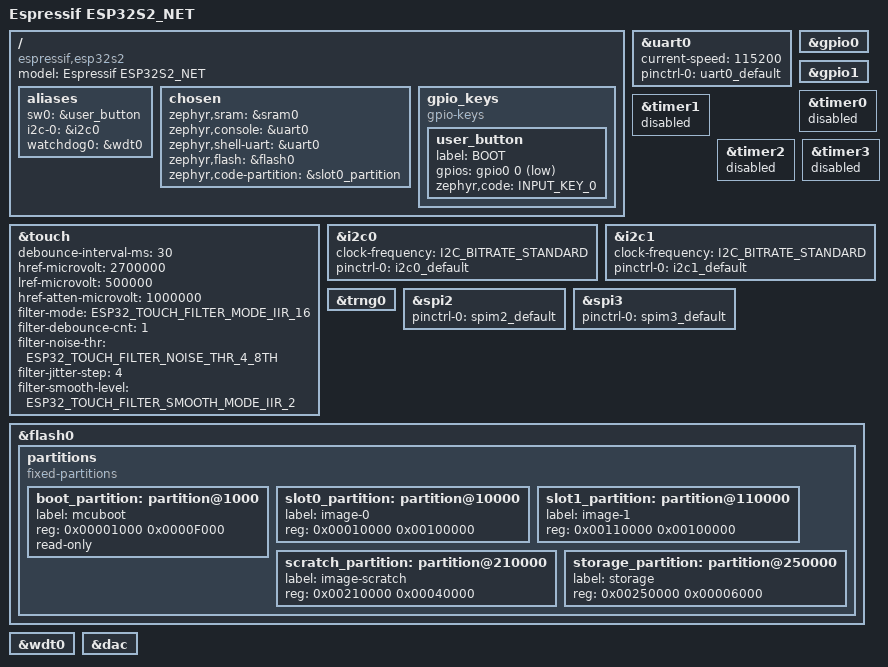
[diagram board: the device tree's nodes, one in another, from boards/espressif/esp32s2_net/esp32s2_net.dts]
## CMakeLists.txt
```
# SPDX-License-Identifier: Apache-2.0

cmake_minimum_required(VERSION 3.20.0)

list(APPEND BOARD_ROOT ${CMAKE_CURRENT_SOURCE_DIR})
find_package(Zephyr REQUIRED HINTS $ENV{ZEPHYR_BASE})

project(esp32s2_net)

target_sources(app PRIVATE 
	src/main.c
	src/fonts/yahei_14.c
	src/lv_wifi.c
	src/wifi_icons.c
	src/mqtt.c
	src/lv_log.c
)
```

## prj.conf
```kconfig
# Remove the banner when start log.
CONFIG_BOOT_BANNER=n

# =============================================================================
# Log configuration
# =============================================================================
CONFIG_LOG=y
CONFIG_LOG_BACKEND_UART=y
# 关闭 shell 日志后端，否则日志由 UART 后端和 shell 后端各打印一遍
# （shell 后端带提示符擦除/重画转义序列，minicom 里表现为整行重复）
CONFIG_SHELL_LOG_BACKEND=n
CONFIG_LOG_PROCESS_THREAD_STACK_SIZE=1024

# =============================================================================
# Shell
# =============================================================================
CONFIG_SHELL=y
CONFIG_SHELL_BACKEND_SERIAL=y
CONFIG_THREAD_MONITOR=y
CONFIG_INIT_STACKS=y
CONFIG_THREAD_STACK_INFO=y
CONFIG_THREAD_NAME=y

# =============================================================================
# Display configuration
# =============================================================================
CONFIG_DISPLAY=y
CONFIG_MIPI_DBI=y
CONFIG_MIPI_DBI_SPI=y
CONFIG_ST7789V=y
CONFIG_LVGL=y
CONFIG_LV_COLOR_DEPTH_16=y
# CONFIG_LV_COLOR_16_SWAP=y  # 若点亮后颜色红蓝反转，再开启
CONFIG_LV_Z_VDB_SIZE=5
CONFIG_LV_Z_BITS_PER_PIXEL=16
CONFIG_LV_Z_MEM_POOL_SIZE=16384
CONFIG_LV_FONT_MONTSERRAT_12=y
CONFIG_LV_FONT_MONTSERRAT_14=y
CONFIG_LV_FONT_MONTSERRAT_16=y
CONFIG_LV_FONT_UNSCII_8=y
CONFIG_MAIN_STACK_SIZE=3072

# =============================================================================
# Wi-Fi configuration（与官方 esp32s2.conf 完全一致，最小验证配置）
# =============================================================================
CONFIG_WIFI=y
CONFIG_WIFI_ESP32=y
CONFIG_WIFI_LOG_LEVEL_INF=y
CONFIG_ESP32_WIFI_STA_AUTO_DHCPV4=y
# 断线自动重连(多扩展器环境下 AP 踢线/信号波动后自动恢复)
CONFIG_ESP32_WIFI_STA_RECONNECT=y
# 临时诊断: 打开 blob 内部调试打印, 抓重连 201 现场
# blob 调试打印: 该 Kconfig 在本版本无消费者, 实际开关是 CONFIG_LOG_DEFAULT_LEVEL
CONFIG_LOG_DEFAULT_LEVEL=3
# iram 优化必须关闭：ESP32-S2 的 IRAM/DRAM 共享同一块 320KB SRAM，
# 开启后 WiFi blob 会多占 ~12.5KB IRAM，与 LVGL 静态缓冲抢内存，
# 导致 dram0_0_seg 链接溢出（实测 overflow ~6.5KB）。
CONFIG_ESP32_WIFI_IRAM_OPT=n
CONFIG_ESP32_WIFI_RX_IRAM_OPT=n

# =============================================================================
# Networking stack（与官方 esp32s2.conf 完全一致）
# =============================================================================
CONFIG_NETWORKING=y
CONFIG_NET_L2_ETHERNET=y
CONFIG_NET_IPV4=y
CONFIG_NET_IPV6=n
CONFIG_NET_DHCPV4=y
CONFIG_NET_LOG=y
CONFIG_NET_SHELL=y
CONFIG_NET_L2_WIFI_SHELL=y
CONFIG_NET_PKT_RX_COUNT=8
CONFIG_NET_PKT_TX_COUNT=8
CONFIG_NET_BUF_RX_COUNT=10
CONFIG_NET_BUF_TX_COUNT=10
CONFIG_NET_MAX_CONTEXTS=12
CONFIG_NET_MAX_CONN=8
CONFIG_NET_TX_STACK_SIZE=2048
CONFIG_NET_RX_STACK_SIZE=2048
# 防止扫描结果事件丢失
CONFIG_NET_MGMT_EVENT_QUEUE_SIZE=16
CONFIG_NET_MGMT_EVENT_QUEUE_TIMEOUT=5000

# =============================================================================
# =============================================================================
# MQTT(屏幕百分比值发布, 参考 samples/net/mqtt_publisher)
# =============================================================================
CONFIG_MQTT_LIB=y
CONFIG_NET_TCP=y
CONFIG_NET_SOCKETS_POSIX_NAMES=y
# POSIX fd 表大小: 默认 4, 0-2 被 stdio 占掉后只剩 1 个 socket 槽,
# MQTT 连接时报 ENFILE(-23), 加大到 16
CONFIG_POSIX_MAX_FDS=16
CONFIG_NET_TCP_WORKQ_STACK_SIZE=1536

# =============================================================================
# Memory / Heap（与官方 esp32s2.conf 一致）
# =============================================================================
CONFIG_HEAP_MEM_POOL_SIZE=61440

# =============================================================================
# Entropy（硬件随机数，Wi-Fi 需要）
# =============================================================================
CONFIG_ENTROPY_ESP32_RNG=y

# =============================================================================
# PSRAM configuration（外部 PSRAM = WROVER N4R2 模组上的 2 MB 芯片）
# =============================================================================
# 硬件事实：ESP32-S2 的 DMA（Wi-Fi MAC、GDMA 均如此）只能访问内部 SRAM
# （SOC_DMA_LOW=0x3FFB0000 ~ SOC_DMA_HIGH=0x40000000），
# PSRAM(0x3F800000) 只有 CPU 能经 cache 访问，任何 DMA 缓冲落入 PSRAM 都会失效。
CONFIG_ESP_SPIRAM=y
CONFIG_SPIRAM_MODE_QUAD=y
CONFIG_SPIRAM_TYPE_ESPPSRAM16=y
CONFIG_SPIRAM_SPEED_40M=y
# 从 PSRAM 中划出 1 MB 作为附加堆（spiram heap）
CONFIG_ESP_SPIRAM_HEAP_SIZE=1048576
# 分配阈值：请求 >= 32768 字节走 PSRAM，其余优先走内部堆。
# 保持 32768 的原因：
#   1) 屏幕 SPI DMA 临时缓冲最大 4092 字节（spi_esp32_spim.c），必须留在内部 RAM；
#   2) 应用想用 PSRAM 时直接 k_malloc(>=32KB) 即可。
CONFIG_ESP_HEAP_MIN_EXTRAM_THRESHOLD=32768

# ❌ 不要启用 CONFIG_SPIRAM_FETCH_INSTRUCTIONS / CONFIG_SPIRAM_RODATA：
#    开启后 esp_psram.c 会调用 mmu_config_psram_text_segment() 等函数，
#    而 Zephyr v3.7.2 的 hal 只在 esp32s3 里实现了这些函数
#    （modules/hal/espressif/zephyr/esp32s3/CMakeLists.txt 才编译
#    mmu_psram_flash.c），esp32s2 会直接链接报错 undefined reference。

# ❌ 不要启用 CONFIG_ESP32_WIFI_NET_ALLOC_SPIRAM：
#    它会把网络栈的 .noinit 静态缓冲池放到 PSRAM；ESP32-S2 上这些缓冲
#    最终被 Wi-Fi MAC 以 DMA 方式访问，PSRAM 不可 DMA，会导致扫描/连接失败。
#    （见 zephyrproject-rtos/zephyr issue #74246、#109602）

# ✅ 依赖一个对 hal_espressif 模块的小 patch（esp32s2/esp_wifi_adapter.c）：
#    1) 去掉 g_wifi_feature_caps 里的 CONFIG_FEATURE_CACHE_TX_BUF_BIT
#       （避免 32×1600B 的 cache-TX 缓冲池耗尽内部堆）；
#    2) *_internal_wrapper 改用 k_aligned_alloc()，保证 Wi-Fi 固件的
#       DMA 缓冲永远落在内部 SRAM。
#    patch 文件保存在工程 patches/ 目录，west update 后需重新应用。
```

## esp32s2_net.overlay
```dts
#include <espressif/esp32s2/esp32s2_wrover_n4r2.dtsi>
#include "boards/espressif/esp32s2_net/esp32s2_net-pinctrl.dtsi"
#include <zephyr/dt-bindings/input/input-event-codes.h>
#include <zephyr/dt-bindings/mipi_dbi/mipi_dbi.h>

/ {
	chosen {
		zephyr,display = &display0;
	};

	display: display {
		status = "okay";
		compatible = "zephyr,mipi-dbi-spi";
		
		spi-dev = <&spi3>;
		dc-gpios = <&gpio0 13 GPIO_ACTIVE_HIGH>;
		reset-gpios = <&gpio0 16 GPIO_ACTIVE_LOW>;
		write-only;	

		#address-cells = <1>;
		#size-cells = <0>;

		display0: display0@0 {
			compatible = "sitronix,st7789v";
			status = "okay";
			reg = <0>;
			mipi-max-frequency = <62500000>;
			mipi-mode = <MIPI_DBI_MODE_SPI_4WIRE>;
			/* Kaluga 液晶是 90 度旋转安装：控制器的 320 栅极线驱动
			 * 玻璃的 320 列（宽），240 源极线驱动 240 行（高）。
			 * 面板的 MADCTL 不可靠，采用软件换轴 + 瓦片转置写入 */
			/* swap-xy; */
		
			height = <240>;
			width = <320>;
			x-offset = <0>;
			y-offset = <0>;
			vcom = <0x2B>;
			gctrl = <0x35>;
			vrhs = <0x0f>;
			vdvs = <0x20>;
			mdac = <0x60>;
			lcm = <0x2C>;
			colmod = <0x55>; /* 16-bit/pixel */
			gamma = <0x01>;
			inversion-off;

			/* 功率与时序控制寄存器字节参数 */
			porch-param  = [0C 0C 00 33 33]; /* Porch setting */
			cmd2en-param = [5a 69 02 01];       /* Command2 Enable Parameter */
			pwctrl1-param = [52 A1];         /* Power control */
			pvgam-param  = [D0 00 02 07 0B 1A 31 54 40 29 12 12 12 17];
			nvgam-param  = [D0 00 02 07 05 15 2D 44 44 1c 18 16 1c 1d];
			ram-param    = [00 F8];          /* RAM control setting */
			rgb-param    = [CD 08 14];       /* RGB Interface Control */	
			
				
		};	
		
	};
	
	backlight: backlight {
		compatible = "gpio-leds";
		bl: bl {
			gpios = <&gpio0 6 GPIO_ACTIVE_HIGH>;
			label = "LCD BackLight";
		};
	};

};

&uart0 {
	status = "okay";
};

&spi3 {
	status = "okay";
	#address-cells = <1>;
	#size-cells = <0>;	
	pinctrl-0 = <&spim3_default>;
	pinctrl-names = "default";
};

&spim3_default {
	group1 {
		pinmux = <SPIM3_MISO_GPIO8>,
			 <SPIM3_MOSI_GPIO9>,
			 <SPIM3_CSEL_GPIO11>;
	};
	group2 {
		pinmux = <SPIM3_SCLK_GPIO15>;
		output-low;
	};
};

&wifi {
	status = "okay";
};

&trng0 {
	status = "okay";
};
```

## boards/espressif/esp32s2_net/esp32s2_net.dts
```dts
/*
 * Copyright (c) 2024 Espressif Systems (Shanghai) Co., Ltd.
 *
 * SPDX-License-Identifier: Apache-2.0
 */

/dts-v1/;

#include <espressif/esp32s2/esp32s2_solo_n4r2.dtsi>
#include "esp32s2_net-pinctrl.dtsi"
#include <zephyr/dt-bindings/input/input-event-codes.h>
#include <zephyr/dt-bindings/input/esp32-touch-sensor-input.h>

/ {
	model = "Espressif ESP32S2_NET";
	compatible = "espressif,esp32s2";

	aliases {
		sw0 = &user_button;
		i2c-0 = &i2c0;
		watchdog0 = &wdt0;
	};

	chosen {
		zephyr,sram = &sram0;
		zephyr,console = &uart0;
		zephyr,shell-uart = &uart0;
		zephyr,flash = &flash0;
		zephyr,code-partition = &slot0_partition;
	};

	gpio_keys {
		compatible = "gpio-keys";
		user_button: user_button {
			label = "BOOT";
			gpios = <&gpio0 0 (GPIO_PULL_UP | GPIO_ACTIVE_LOW)>;
			zephyr,code = <INPUT_KEY_0>;
		};
	};
};

&uart0 {
	status = "okay";
	current-speed = <115200>;
	pinctrl-0 = <&uart0_default>;
	pinctrl-names = "default";
};

&gpio0 {
	status = "okay";
};

&gpio1 {
	status = "okay";
};

&touch {
	debounce-interval-ms = <30>;
	href-microvolt = <2700000>;
	lref-microvolt = <500000>;
	href-atten-microvolt = <1000000>;
	filter-mode = <ESP32_TOUCH_FILTER_MODE_IIR_16>;
	filter-debounce-cnt = <1>;
	filter-noise-thr = <ESP32_TOUCH_FILTER_NOISE_THR_4_8TH>;
	filter-jitter-step = <4>;
	filter-smooth-level = <ESP32_TOUCH_FILTER_SMOOTH_MODE_IIR_2>;
};

&timer0 {
	status = "disabled";
};

&timer1 {
	status = "disabled";
};

&timer2 {
	status = "disabled";
};

&timer3 {
	status = "disabled";
};

&i2c0 {
	status = "okay";
	clock-frequency = <I2C_BITRATE_STANDARD>;
	pinctrl-0 = <&i2c0_default>;
	pinctrl-names = "default";
};

&i2c1 {
	clock-frequency = <I2C_BITRATE_STANDARD>;
	pinctrl-0 = <&i2c1_default>;
	pinctrl-names = "default";
};

&trng0 {
	status = "okay";
};

&spi2 {
	#address-cells = <1>;
	#size-cells = <0>;
	status = "okay";
	pinctrl-0 = <&spim2_default>;
	pinctrl-names = "default";
};

&spi3 {
	#address-cells = <1>;
	#size-cells = <0>;
	status = "okay";
	pinctrl-0 = <&spim3_default>;
	pinctrl-names = "default";
};


&flash0 {
	status = "okay";

	partitions {
		compatible = "fixed-partitions";
		#address-cells = <1>;
		#size-cells = <1>;

		/* Reserve 60kB for the bootloader */
		boot_partition: partition@1000 {
			label = "mcuboot";
			reg = <0x00001000 0x0000F000>;
			read-only;
		};

		/* Reserve 1024kB for the application in slot 0 */
		slot0_partition: partition@10000 {
			label = "image-0";
			reg = <0x00010000 0x00100000>;
		};

		/* Reserve 1024kB for the application in slot 1 */
		slot1_partition: partition@110000 {
			label = "image-1";
			reg = <0x00110000 0x00100000>;
		};

		/* Reserve 256kB for the scratch partition */
		scratch_partition: partition@210000 {
			   label = "image-scratch";
			   reg = <0x00210000 0x00040000>;
		};

		storage_partition: partition@250000 {
			label = "storage";
			reg = <0x00250000 0x00006000>;
		};
	};
};

&wdt0 {
	status = "okay";
};

&dac {
	status = "okay";
};
```

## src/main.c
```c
#include <zephyr/kernel.h>
#include <zephyr/device.h>
#include <zephyr/logging/log.h>
#include <errno.h>
#include <zephyr/drivers/gpio.h>
#include <zephyr/drivers/display.h>
#include <lvgl.h>
#include <zephyr/net/wifi_mgmt.h>
#include <zephyr/net/ethernet.h>
#include "fonts/yahei_14.h"
#include "lv_wifi.h"
#include "lv_log.h"
#include "mqtt.h"

LOG_MODULE_REGISTER(main, LOG_LEVEL_INF);

static const struct gpio_dt_spec bl = GPIO_DT_SPEC_GET(DT_NODELABEL(bl),gpios);
static const struct device *display_dev = DEVICE_DT_GET(DT_CHOSEN(zephyr_display));
static lv_style_t style_title;
static lv_style_t label_style;
static lv_style_t arc_bg_style;
static lv_style_t indicator_style;
static lv_obj_t *scr; 
static lv_obj_t *t;
static lv_obj_t *arc;
static lv_obj_t *label; 
#define WIFI_SSID "QHDTUC2.4"
#define WIFI_PASSWORD "QHDTUC11305610"
static int connected;
static struct net_mgmt_event_callback wifi_mgmt_cb;

#define ACCENT lv_color_hex(0x6366f1)
#define MASK_WIDTH 250
#define MASK_HEIGHT 25

static void handle_wifi_connect_result(struct net_mgmt_event_callback *cb)
{
	const struct wifi_status *status = (const struct wifi_status *)cb->info;
	
	if (status->status) {
		LOG_ERR("wifi connect failed %d", status->status);
	} else {
		LOG_INF("wifi connected");
		connected = 1;
	}
}

static void wifi_event_handler(struct net_mgmt_event_callback *cb, uint32_t mgmt_event, struct net_if *iface)
{
	if (mgmt_event == NET_EVENT_WIFI_CONNECT_RESULT) {
		handle_wifi_connect_result(cb);
	}
}

/* 这里是wifi阻塞式连接方式 */
void wifi_connect(void)
{
	struct net_if *iface = net_if_get_default();
	
	static struct wifi_connect_req_params params = {
		.ssid		= WIFI_SSID,
		.ssid_length	= sizeof(WIFI_SSID) -1,
		.psk		= WIFI_PASSWORD,
		.psk_length	= sizeof(WIFI_PASSWORD) -1,
		.channel	= 0,
		.security	= WIFI_SECURITY_TYPE_PSK,
		.band		= WIFI_FREQ_BAND_2_4_GHZ,
		.mfp		= WIFI_MFP_OPTIONAL,
	};
	
	net_mgmt_init_event_callback(&wifi_mgmt_cb,
                                 wifi_event_handler,
                                 NET_EVENT_WIFI_CONNECT_RESULT);
	net_mgmt_add_event_callback(&wifi_mgmt_cb);

	connected = 0;

	int nr_tries = 10;
	while (nr_tries-- > 0) {
		int ret = net_mgmt(NET_REQUEST_WIFI_CONNECT, iface,
				   &params,
				   sizeof(struct wifi_connect_req_params));
	if (ret == 0) {
		break;
	}
		LOG_INF("Waiting for Wi-Fi interface...");
		k_msleep(500);
	}

	/* 等待连接完成 */
	while (connected == 0) {
		k_msleep(100);
	}

}

/* 这里是wifi异步连接方式 */
void wifi_connect_async(void)
{
    struct net_if *iface = net_if_get_default();

    static struct wifi_connect_req_params params = {
        .ssid        = WIFI_SSID,
        .ssid_length = sizeof(WIFI_SSID) - 1,
        .psk         = WIFI_PASSWORD,
        .psk_length  = sizeof(WIFI_PASSWORD) - 1,
        .channel     = 0,
        .security    = WIFI_SECURITY_TYPE_PSK,
	.band	     = WIFI_FREQ_BAND_2_4_GHZ,
	.mfp         = WIFI_MFP_OPTIONAL,
    };

    net_mgmt_init_event_callback(&wifi_mgmt_cb,
                                 wifi_event_handler,
                                 NET_EVENT_WIFI_CONNECT_RESULT |
                                 NET_EVENT_WIFI_DISCONNECT_RESULT);
    net_mgmt_add_event_callback(&wifi_mgmt_cb);

    connected = 0;

    /* 等待驱动初始化完成再发起连接 */
    k_sleep(K_SECONDS(2));

    int nr_tries = 10;
    while (nr_tries-- > 0) {
        int ret = net_mgmt(NET_REQUEST_WIFI_CONNECT, iface,
                           &params,
                           sizeof(struct wifi_connect_req_params));
        if (ret == 0) {
            LOG_INF("Wi-Fi connect request sent, waiting for result...");
            return;
        }
        LOG_WRN("Wi-Fi connect request failed (%d), retrying...", ret);
        k_sleep(K_MSEC(500));
    }

    LOG_ERR("All Wi-Fi connect requests failed");
}

void lv_example_label_5(void)
{
	static lv_anim_t animation_template;
	static lv_style_t label_style;

	lv_anim_init(&animation_template);
	lv_anim_set_delay(&animation_template, 1000);
	lv_anim_set_repeat_delay(&animation_template, 3000);
	
	lv_style_init(&label_style);
	lv_style_set_anim(&label_style, &animation_template);
	lv_style_set_text_color(&label_style, lv_color_hex(0x000FFF));
	
	lv_obj_t *label1 = lv_label_create(lv_scr_act());
	lv_label_set_long_mode(label1, LV_LABEL_LONG_SCROLL_CIRCULAR); /* Circular scroll */
	lv_obj_set_width(label1, 200);
	lv_label_set_text(label1, "Nothing in the world can take the place of persistence.");
	lv_obj_align(label1, LV_ALIGN_CENTER, 0, 100);
	lv_obj_add_style(label1, &label_style, LV_STATE_DEFAULT);
}


static void add_mask_event_cb(lv_event_t * e)
{
	static lv_draw_mask_map_param_t m;
	static int16_t mask_id;

	lv_event_code_t code = lv_event_get_code(e);
	lv_obj_t * obj = lv_event_get_target(e);
	lv_opa_t * mask_map = lv_event_get_user_data(e);
	if(code == LV_EVENT_COVER_CHECK) {
	lv_event_set_cover_res(e, LV_COVER_RES_MASKED);
	}
	else if(code == LV_EVENT_DRAW_MAIN_BEGIN) {
	lv_draw_mask_map_init(&m, &obj->coords, mask_map);
	mask_id = lv_draw_mask_add(&m, NULL);

	}
	else if(code == LV_EVENT_DRAW_MAIN_END) {
	lv_draw_mask_free_param(&m);
	lv_draw_mask_remove_id(mask_id);
	}
}

/**
 * Draw label with gradient color
 */

 void lv_example_label_4(void)
{
	/* Create the mask of a text by drawing it to a canvas.
	 * 缓冲放 PSRAM(.ext_ram.bss 段, 启动时自动清零):
	 * 仅 CPU 读写、无 DMA, 6.25KB 内部 DRAM 留给网络栈 */
	static lv_opa_t mask_map[MASK_WIDTH * MASK_HEIGHT]
		__attribute__((section(".ext_ram.bss")));

	/*Create a "8 bit alpha" canvas and clear it*/
	lv_obj_t * canvas = lv_canvas_create(lv_scr_act());
	lv_canvas_set_buffer(canvas, mask_map, MASK_WIDTH, MASK_HEIGHT, LV_IMG_CF_ALPHA_8BIT);
	lv_canvas_fill_bg(canvas, lv_color_black(), LV_OPA_TRANSP);

	/*Draw a label to the canvas. The result "image" will be used as mask*/
	lv_draw_label_dsc_t label_dsc;
	lv_draw_label_dsc_init(&label_dsc);
	label_dsc.color = lv_color_white();
	label_dsc.align = LV_TEXT_ALIGN_CENTER;
	label_dsc.font = &yahei_14;
	lv_canvas_draw_text(canvas, 0, 5, MASK_WIDTH, &label_dsc, "欲买桂花同载酒, 终不似, 少年游.");

	/*The mask is reads the canvas is not required anymore*/
	lv_obj_del(canvas);

	/* Create an object from where the text will be masked out.
	* Now it's a rectangle with a gradient but it could be an image too*/
	lv_obj_t * grad = lv_obj_create(lv_scr_act());
	lv_obj_set_size(grad, MASK_WIDTH, MASK_HEIGHT);
	lv_obj_align(grad, LV_ALIGN_TOP_RIGHT, -35, 20);

	/* ===== 新增：去除默认的边框、轮廓和内边距 ===== */
	lv_obj_set_style_border_width(grad, 0, 0);       // 去除边框
	lv_obj_set_style_outline_width(grad, 0, 0);      // 去除轮廓线
	lv_obj_set_style_shadow_width(grad, 0, 0);       // 去除阴影
	lv_obj_set_style_pad_all(grad, 0, 0);            // 去除内边距(防止mask偏移)
	lv_obj_set_style_radius(grad, 0, 0);             // 去除圆角(可选)

	lv_obj_set_style_bg_color(grad, lv_color_hex(0x00ff00), 0);
	lv_obj_set_style_bg_grad_color(grad, lv_color_hex(0xff0000), 0);
	lv_obj_set_style_bg_grad_dir(grad, LV_GRAD_DIR_HOR, 0);
	lv_obj_add_event_cb(grad, add_mask_event_cb, LV_EVENT_ALL, mask_map);
}

void lvgl_ui_test(void)
{
	k_sleep(K_MSEC(100));

	LOG_INF("Hello Zephyr.");

	/* LVGL */
	lv_style_init(&style_title);
	lv_style_set_text_color(&style_title, lv_color_hex(0xFF0000));
	lv_style_set_text_font(&style_title, &lv_font_montserrat_14);
	// lv_style_set_text_font(&style_title, &lv_font_unscii_8);

	/* label style config */
	lv_style_init(&label_style);
	lv_style_set_text_color(&label_style, lv_color_hex(0x00FF00));
	lv_style_set_text_font(&label_style, &lv_font_montserrat_14);

	/* arc back ground style config */
	lv_style_init(&arc_bg_style);
	lv_style_set_arc_color(&arc_bg_style, ACCENT);
	lv_style_set_arc_width(&arc_bg_style, 14);
	lv_style_set_arc_opa(&arc_bg_style, (255 * 20 / 100));
	lv_style_set_arc_rounded(&arc_bg_style, true);

	/* indicator style config */
	lv_style_init(&indicator_style);
	lv_style_set_arc_color(&indicator_style, ACCENT);
	lv_style_set_arc_width(&indicator_style, 14);
	lv_style_set_arc_rounded(&indicator_style, true);

	scr = lv_scr_act();
	lv_obj_set_style_bg_color(scr, lv_color_black(), 0);
	lv_obj_set_style_bg_opa(scr, LV_OPA_COVER, 0);

	t = lv_label_create(scr);
	lv_label_set_text(t, "MQTT Client Terminal");
	lv_obj_add_style(t, &style_title, 0);
	lv_obj_align(t, LV_ALIGN_TOP_LEFT, 0, 0);

	/* test arc */
	arc = lv_arc_create(scr);
	lv_obj_set_size(arc, 140, 140);
	lv_arc_set_range(arc, 0, 100);
	lv_arc_set_value(arc, 0);
	lv_obj_add_style(arc, &arc_bg_style, LV_PART_MAIN);
	lv_obj_add_style(arc, &indicator_style, LV_PART_INDICATOR);
	lv_obj_center(arc);
	
	/* arc counter label */
	label = lv_label_create(arc);
	lv_obj_add_style(label, &label_style, 0);
	lv_obj_center(label);

	/* Circular scroll */
	lv_example_label_5();

	/* Rainbow text */
	lv_example_label_4();
}

int main(void)
{
	int ret;

	if (!gpio_is_ready_dt(&bl)) {
		LOG_ERR("device bl get failed!");
	}

	/* 上电即点亮背光 */
	ret = gpio_pin_configure_dt(&bl, GPIO_OUTPUT_INIT_HIGH);
	if (ret != 0) {
		LOG_ERR("Error %d: failed to configure output on pin %d", ret, bl.pin);
	}

	/* 打开面板显示（DISP ON），驱动初始化后默认是关闭状态 */
	if (!device_is_ready(display_dev)) {
		LOG_ERR("Display device not ready");
		return 0;
	}
	display_blanking_off(display_dev);
	LOG_INF("display blanking off");
	/* 面板 DISP ON 后需要一段稳定时间才能可靠接收第一批像素数据，
	 * 否则首帧的前几个刷新块会被丢弃（表现为屏幕顶部内容缺失） */

	lvgl_ui_test();
	wifi_statusbar_init();
	lv_log_init();
	mqtt_client_start();

	static int8_t counter = 0;
	static bool direction = 0;

	wifi_connect_async();

	while (1) {
		uint32_t ms = lv_timer_handler();
		lv_arc_set_value(arc, counter);
		lv_label_set_text_fmt(label, "%d%%", counter);
		if (!direction) counter++;
		else counter--;
		if (counter == 100 || counter == 0) {
			 direction = !direction;
		}
		mqtt_set_percent(counter);
		k_msleep(30);
	}
	return 0;
}
```

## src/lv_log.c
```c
/*
 * 屏幕日志面板: 注册一个自定义 Zephyr 日志后端, 把日志实时显示到屏幕上。
 *
 * 工作原理:
 *  - LOG_MODE_IMMEDIATE 下, 后端 process() 在日志产生者上下文(任意线程)
 *    被同步调用, 用 log_output 格式化后经 char_out 进入行环形缓冲;
 *  - 行环/行缓冲放在 PSRAM(.ext_ram.bss), 纯 CPU 访问, 不占内部 DRAM;
 *  - LVGL 定时器每 300ms 在 LVGL 上下文把新行更新到底部半透明面板。
 */
#include <zephyr/kernel.h>
#include <zephyr/logging/log.h>
#include <zephyr/logging/log_backend.h>
#include <zephyr/logging/log_backend_std.h>
#include <zephyr/logging/log_output.h>
#include <zephyr/logging/log_ctrl.h>
#include <zephyr/logging/log_core.h>
#include <lvgl.h>

LOG_MODULE_REGISTER(lv_log, LOG_LEVEL_INF);

/* 行环: 8 行 x 112 字符, 放 PSRAM */
#define LOG_LINE_MAX   112
#define LOG_RING_LINES 8
#define DISP_LINES     4	/* 屏幕上显示的最近行数 */
#define DISP_CHARS     44	/* 每显示行最大字符数(320 宽 12px 字体的上限) */

static char ring[LOG_RING_LINES][LOG_LINE_MAX + 1]
	__attribute__((section(".ext_ram.bss")));
static char cur_line[LOG_LINE_MAX + 1]
	__attribute__((section(".ext_ram.bss")));
static uint32_t cur_len;
static uint32_t ring_wr;	/* 已写入行数(单调递增) */
static uint32_t ring_rd;	/* 已被屏幕消费的行数 */
static struct k_spinlock ring_lock;

static lv_obj_t *log_label;

/* ==== log_output 的字符回调(日志产生者上下文, 可能来自 ISR) ====
 * 注意: 必须返回"已消费的字节数"——log_output 的 buffer_write() 依赖
 * 返回值推进 buf/len, 返回 void 会导致用垃圾值推进指针而崩溃 */
static int char_out(uint8_t *data, size_t length, void *ctx)
{
	ARG_UNUSED(ctx);

	k_spinlock_key_t key = k_spin_lock(&ring_lock);

	for (size_t i = 0; i < length; i++) {
		char c = (char)data[i];

		if (c == '\r') {
			continue;
		}

		if (c == '\n' || cur_len >= LOG_LINE_MAX) {
			/* 提交当前行 */
			cur_line[cur_len] = '\0';
			strncpy(ring[ring_wr % LOG_RING_LINES], cur_line,
				LOG_LINE_MAX);
			ring[ring_wr % LOG_RING_LINES][LOG_LINE_MAX] = '\0';
			ring_wr++;
			cur_len = 0;

			if (c == '\n') {
				continue;
			}
		}

		cur_line[cur_len++] = c;
	}

	k_spin_unlock(&ring_lock, key);

	return length;
}

/* log_output 内部缓冲 */
static uint8_t log_buf[128];

LOG_OUTPUT_DEFINE(lv_log_output, char_out, log_buf, sizeof(log_buf));

/* ==== 日志后端 API ==== */
static uint32_t log_format_current;	/* 0 = LOG_OUTPUT_TEXT 默认格式 */

static void process(const struct log_backend *const backend,
		    union log_msg_generic *msg)
{
	ARG_UNUSED(backend);

	uint32_t flags = log_backend_std_get_flags();
	log_format_func_t log_output_func =
		log_format_func_t_get(log_format_current);

	log_output_func(&lv_log_output, &msg->log, flags);
}

static void dropped(const struct log_backend *const backend, uint32_t cnt)
{
	ARG_UNUSED(backend);
	ARG_UNUSED(cnt);
}

static void panic(struct log_backend const *const backend)
{
	ARG_UNUSED(backend);
}

static void lv_log_backend_init(const struct log_backend *const backend)
{
	ARG_UNUSED(backend);
}

static int is_ready(const struct log_backend *const backend)
{
	ARG_UNUSED(backend);
	return 1;
}

static int format_set(const struct log_backend *const backend,
		      uint32_t log_type)
{
	ARG_UNUSED(backend);
	log_format_current = log_type;
	return 0;
}

static const struct log_backend_api log_backend_lvlog_api = {
	.process = process,
	.dropped = dropped,
	.panic = panic,
	.init = lv_log_backend_init,
	.is_ready = is_ready,
	.format_set = format_set,
};

LOG_BACKEND_DEFINE(log_backend_lvlog, log_backend_lvlog_api, false, NULL);

/* ==== LVGL 侧: 定时器把新日志更新到面板 ==== */
static char disp_buf[DISP_LINES * (DISP_CHARS + 3) + 1]
	__attribute__((section(".ext_ram.bss")));

static void log_panel_timer_cb(lv_timer_t *timer)
{
	ARG_UNUSED(timer);

	/* 快照消费计数 */
	k_spinlock_key_t key = k_spin_lock(&ring_lock);
	uint32_t wr = ring_wr;
	uint32_t rd = ring_rd;
	k_spin_unlock(&ring_lock, key);

	uint32_t pending = wr - rd;
	if (pending == 0) {
		return;
	}

	/* 取最近 DISP_LINES 行(旧→新)拼成文本 */
	if (pending > DISP_LINES) {
		rd = wr - DISP_LINES;
	}

	uint32_t pos = 0;
	for (uint32_t i = 0; i < DISP_LINES && rd + i < wr; i++) {
		const char *line = ring[(rd + i) % LOG_RING_LINES];
		uint32_t n = 0;

		while (line[n] && n < DISP_CHARS && pos < sizeof(disp_buf) - 2) {
			disp_buf[pos++] = line[n++];
		}
		if (line[n]) {
			/* 截断标记 */
			if (pos < sizeof(disp_buf) - 3) {
				disp_buf[pos++] = '.';
				disp_buf[pos++] = '.';
			}
		}
		if (pos < sizeof(disp_buf) - 2) {
			disp_buf[pos++] = '\n';
		}
	}
	disp_buf[pos] = '\0';

	lv_label_set_text(log_label, disp_buf);

	/* 标记已消费 */
	key = k_spin_lock(&ring_lock);
	ring_rd = wr;
	k_spin_unlock(&ring_lock, key);
}

/* ==== 公开接口 ==== */
void lv_log_init(void)
{
	/* 底部半透明面板 */
	lv_obj_t *panel = lv_obj_create(lv_scr_act());
	lv_obj_set_size(panel, LV_HOR_RES, 70);
	lv_obj_align(panel, LV_ALIGN_BOTTOM_MID, 0, 0);
	lv_obj_set_style_bg_color(panel, lv_color_black(), 0);
	lv_obj_set_style_bg_opa(panel, LV_OPA_50, 0);
	lv_obj_set_style_border_width(panel, 0, 0);
	lv_obj_set_style_pad_all(panel, 3, 0);

	log_label = lv_label_create(panel);
	lv_label_set_text(log_label, "");
	lv_obj_set_style_text_font(log_label, &lv_font_montserrat_12, 0);
	lv_obj_set_style_text_color(log_label, lv_color_white(), 0);
	lv_obj_set_width(log_label, LV_HOR_RES - 6);
	lv_label_set_long_mode(log_label, LV_LABEL_LONG_DOT);

	/* 每 300ms 拉取新日志 */
	lv_timer_create(log_panel_timer_cb, 300, NULL);

	/* 注册显示日志后端 */
	log_backend_activate(&log_backend_lvlog, NULL);
}
```

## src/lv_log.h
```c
#ifndef __LV_LOG_H__
#define __LV_LOG_H__

#ifdef __cplusplus
extern "C" {
#endif

/** 创建屏幕日志面板 + 注册显示日志后端(在 LVGL 初始化后调用) */
void lv_log_init(void);

#ifdef __cplusplus
}
#endif

#endif /* __LV_LOG_H__ */
```

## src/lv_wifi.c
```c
#include <lvgl.h>
#include <zephyr/logging/log.h>
#include <zephyr/net/net_mgmt.h>
#include <zephyr/net/wifi_mgmt.h>
#include "lv_wifi.h"

LOG_MODULE_REGISTER(wifi_statusbar, LOG_LEVEL_INF);

/* ==== UI 对象 ==== */
static lv_obj_t *statusbar;
static lv_obj_t *wifi_icon;
static lv_obj_t *rssi_label;
static lv_obj_t *ssid_label;

/* ==== 根据 RSSI 选择 WIFI 图标 ==== */
static const lv_img_dsc_t *get_wifi_icon_img(int8_t rssi)
{
	if (rssi >= -50) return &wifi_4;	/* 信号强:4 格 */
	if (rssi >= -65) return &wifi_3;	/* 信号中:3 格 */
	if (rssi >= -75) return &wifi_2;	/* 信号弱:2 格 */
	return &wifi_1;				/* 信号极弱:1 格 */
}

/* ===== 更新状态栏显示 (经 lv_async_call 在 LVGL 上下文执行) ==== */
static void update_statusbar(void *param)
{
	struct wifi_iface_status *s = (struct wifi_iface_status *)param;

	if (!statusbar) {
		if (s) k_free(s);
		return;
	}

	if (s) {
		/* 有数据, 更新 WiFi 信息 */
		lv_img_set_src(wifi_icon, get_wifi_icon_img(s->rssi));
		lv_obj_clear_flag(wifi_icon, LV_OBJ_FLAG_HIDDEN);

		char rssi_buf[8];
		snprintf(rssi_buf, sizeof(rssi_buf), "%d", s->rssi);
		lv_label_set_text(rssi_label, rssi_buf);

		lv_label_set_text(ssid_label, s->ssid);

		k_free(s);
	} else {
		/* 无数据(断开连接), 显示默认状态 */
		lv_obj_add_flag(wifi_icon, LV_OBJ_FLAG_HIDDEN);
		lv_label_set_text(rssi_label, "--");
		lv_label_set_text(ssid_label, "Disconnected");
	}
}


/* ==== 创建状态栏 UI ==== */
void statusbar_create(void)
{
	/* status bar: 占满顶行, 内容靠右 */
	statusbar = lv_obj_create(lv_scr_act());

	lv_obj_set_size(statusbar, LV_HOR_RES, 22);
	lv_obj_align(statusbar, LV_ALIGN_TOP_RIGHT, 0, 0);
	lv_obj_set_style_bg_opa(statusbar, LV_OPA_TRANSP, 0);
	lv_obj_set_style_border_width(statusbar, 0, 0);
	lv_obj_set_style_pad_all(statusbar, 0, 0);
	lv_obj_set_style_pad_right(statusbar, 4, 0);	/* 右边留 4px, 4 格信号条不贴屏幕边缘 */
	lv_obj_set_flex_flow(statusbar, LV_FLEX_FLOW_ROW);
	lv_obj_set_flex_align(statusbar, LV_FLEX_ALIGN_END,
			      LV_FLEX_ALIGN_CENTER,
			      LV_FLEX_ALIGN_CENTER);
	lv_obj_set_style_pad_column(statusbar, 4, 0);

	/* SSID name(flex 行最左) */
	ssid_label = lv_label_create(statusbar);
	lv_label_set_text(ssid_label, "Not Connected");
	lv_obj_set_style_text_font(ssid_label, &lv_font_montserrat_12, 0);
	lv_obj_set_style_text_color(ssid_label, lv_color_hex(0xFFFFFF), 0);
	lv_obj_set_width(ssid_label, 90);	/* 限制宽度 */
	lv_label_set_long_mode(ssid_label, LV_LABEL_LONG_DOT);	/* 超长显示 */

	/* RSSI(flex 行中间) */
	rssi_label = lv_label_create(statusbar);
	lv_label_set_text(rssi_label, "--");
	lv_obj_set_style_text_font(rssi_label, &lv_font_montserrat_12, 0);
	lv_obj_set_style_text_color(rssi_label, lv_color_hex(0xFFFFFF), 0);

	/* wifi 图标(信号条, 最后创建 = flex 行最右端) */
	wifi_icon = lv_img_create(statusbar);
	lv_img_set_src(wifi_icon, &wifi_4);
	lv_obj_set_style_img_recolor(wifi_icon, lv_color_white(), 0);
	lv_obj_set_style_img_recolor_opa(wifi_icon, LV_OPA_COVER, 0);
	lv_obj_add_flag(wifi_icon, LV_OBJ_FLAG_HIDDEN);	/* 连上后才显示 */
}

/* === WIFI 事件回调 (运行在网络线程) === */
static struct net_mgmt_event_callback wifi_cb;
static bool is_connected;

static void wifi_event_handler(struct net_mgmt_event_callback *cb,
			       uint32_t mgmt_event,
			       struct net_if *iface)
{
	struct wifi_iface_status status = {0};

	switch (mgmt_event) {

	case NET_EVENT_WIFI_CONNECT_RESULT:
		LOG_INF("Wi-Fi connected");
		is_connected = true;
		if (net_mgmt(NET_REQUEST_WIFI_IFACE_STATUS, iface,
			     &status, sizeof(status)) == 0) {
			struct wifi_iface_status *copy = k_malloc(sizeof(*copy));
			if (copy) {
				memcpy(copy, &status, sizeof(*copy));
				lv_async_call(update_statusbar, copy);
			}
		}
		break;

	case NET_EVENT_WIFI_DISCONNECT_RESULT:
		LOG_INF("Wi-Fi disconnected");
		is_connected = false;
		lv_async_call(update_statusbar, NULL);
		break;
	}
}

/* ==== 周期性刷新信号强度 (LVGL 定时器, 运行在 LVGL 上下文) ==== */
static void statusbar_refresh_timer_cb(lv_timer_t *timer)
{
	struct wifi_iface_status status = {0};
	struct net_if *iface = net_if_get_default();

	if (!is_connected || !iface) {
		return;
	}

	if (net_mgmt(NET_REQUEST_WIFI_IFACE_STATUS, iface,
		     &status, sizeof(status)) != 0) {
		return;
	}

	/* 已在 LVGL 上下文, 直接更新 UI */
	lv_img_set_src(wifi_icon, get_wifi_icon_img(status.rssi));
	lv_obj_clear_flag(wifi_icon, LV_OBJ_FLAG_HIDDEN);

	char rssi_buf[8];
	snprintf(rssi_buf, sizeof(rssi_buf), "%d", status.rssi);
	lv_label_set_text(rssi_label, rssi_buf);
	lv_label_set_text(ssid_label, status.ssid);
}

/* ===== 公开初始化接口 ===== */
void wifi_statusbar_init(void)
{
	statusbar_create();

	net_mgmt_init_event_callback(&wifi_cb, wifi_event_handler,
				     NET_EVENT_WIFI_CONNECT_RESULT |
				     NET_EVENT_WIFI_DISCONNECT_RESULT);
	net_mgmt_add_event_callback(&wifi_cb);

	/* 每 3 秒轮询一次 RSSI, 实时刷新信号值与信号条 */
	lv_timer_create(statusbar_refresh_timer_cb, 3000, NULL);
}
```

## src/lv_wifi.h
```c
#ifndef __LV_WIFI_H__
#define __LV_WIFI_H__

#include <lvgl.h>

#ifdef __cplusplus
extern "C" {
#endif

/* WiFi 信号条图标(定义在 wifi_icons.c) */
LV_IMG_DECLARE(wifi_4);
LV_IMG_DECLARE(wifi_3);
LV_IMG_DECLARE(wifi_2);
LV_IMG_DECLARE(wifi_1);

void wifi_statusbar_init(void);

#ifdef __cplusplus
}
#endif

#endif /* __LV_WIFI_H__ */
```

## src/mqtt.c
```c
/*
 * MQTT 客户端: 每 100ms 向 broker 发布一次屏幕中间的百分比值。
 * 参考 Zephyr 官方示例 samples/net/mqtt_publisher。
 */
#include <zephyr/kernel.h>
#include <zephyr/logging/log.h>
#include <zephyr/net/mqtt.h>
#include <zephyr/net/socket.h>
#include <zephyr/net/net_ip.h>
#include <string.h>
#include <stdio.h>

#include "mqtt.h"

LOG_MODULE_REGISTER(mqtt_client, LOG_LEVEL_INF);

/* ==== 配置 ==== */
/* broker = 测试电脑(运行 mosquitto 的主机)的 IP。
 * 注意: 电脑 IP 是 DHCP 动态分配的, 变了要改这里 */
#define MQTT_BROKER_ADDR	"192.168.1.77"
#define MQTT_BROKER_PORT	1883
#define MQTT_CLIENT_ID		"esp32s2_kaluga"
#define MQTT_TOPIC		"esp32s2/percent"
#define MQTT_PUBLISH_PERIOD_MS	100
#define MQTT_RECONNECT_DELAY_MS	2000

/* ==== 缓冲区 ==== */
static uint8_t rx_buffer[128];
static uint8_t tx_buffer[128];

/* MQTT client context */
static struct mqtt_client client_ctx;

/* Broker 地址 */
static struct sockaddr_storage broker;

/* 主循环更新的百分比值 */
static volatile int8_t percent_value;

/* 连接状态(由事件回调维护) */
static volatile bool mqtt_connected;

/* ==== 线程 ==== */
K_THREAD_STACK_DEFINE(mqtt_stack, 1536);
static struct k_thread mqtt_thread_data;

/* ==== 事件回调 ==== */
static void mqtt_evt_handler(struct mqtt_client *client,
			     const struct mqtt_evt *evt)
{
	switch (evt->type) {
	case MQTT_EVT_CONNACK:
		if (evt->result == 0) {
			LOG_INF("MQTT connected to broker");
			mqtt_connected = true;
		} else {
			LOG_ERR("MQTT connection rejected: %d", evt->result);
			mqtt_connected = false;
		}
		break;

	case MQTT_EVT_DISCONNECT:
		LOG_INF("MQTT disconnected: %d", evt->result);
		mqtt_connected = false;
		break;

	/* PUBACK/PUBREC/PUBREL/PUBCOMP 只在 QoS>0 时需要处理,
	 * 本项目用 QoS 0, 忽略即可 */
	default:
		break;
	}
}

/* ==== 初始化 ==== */
static void init_context(void)
{
	mqtt_client_init(&client_ctx);

	client_ctx.broker = &broker;
	client_ctx.evt_cb = mqtt_evt_handler;
	client_ctx.client_id.utf8 = (uint8_t *)MQTT_CLIENT_ID;
	client_ctx.client_id.size = sizeof(MQTT_CLIENT_ID) - 1;
	client_ctx.password = NULL;
	client_ctx.user_name = NULL;
	client_ctx.protocol_version = MQTT_VERSION_3_1_1;
	client_ctx.transport.type = MQTT_TRANSPORT_NON_SECURE;

	client_ctx.rx_buf = rx_buffer;
	client_ctx.rx_buf_size = sizeof(rx_buffer);
	client_ctx.tx_buf = tx_buffer;
	client_ctx.tx_buf_size = sizeof(tx_buffer);
}

/* 解析 broker 地址(IP + 端口) */
static int broker_init(void)
{
	struct zsock_addrinfo *addr;
	struct zsock_addrinfo hints = {
		.ai_family = AF_INET,
		.ai_socktype = SOCK_STREAM,
	};
	char port_str[8];

	snprintf(port_str, sizeof(port_str), "%d", MQTT_BROKER_PORT);

	int rc = zsock_getaddrinfo(MQTT_BROKER_ADDR, port_str, &hints, &addr);
	if (rc != 0) {
		LOG_ERR("Broker address resolution failed: %d", rc);
		return rc;
	}

	memcpy(&broker, addr->ai_addr, addr->ai_addrlen);
	zsock_freeaddrinfo(addr);
	return 0;
}

/* ==== 线程主体 ==== */
static void mqtt_thread_fn(void *a, void *b, void *c)
{
	ARG_UNUSED(a);
	ARG_UNUSED(b);
	ARG_UNUSED(c);

	init_context();

	while (1) {
		/* WiFi 没起来/broker 不可达时循环重试 */
		if (broker_init() != 0) {
			k_msleep(MQTT_RECONNECT_DELAY_MS);
			continue;
		}

		int rc = mqtt_connect(&client_ctx);
		if (rc != 0) {
			LOG_WRN("MQTT connect failed %d, retry in %d s",
				rc, MQTT_RECONNECT_DELAY_MS / 1000);
			/* 注意: Zephyr 3.7 的 mqtt_connect 出错时只重置状态、
			 * 不关闭 socket(fd 泄漏), 必须手动 disconnect 清理 */
			mqtt_disconnect(&client_ctx);
			k_msleep(MQTT_RECONNECT_DELAY_MS);
			continue;
		}

		/* mqtt_connect 非阻塞: CONNECT 包已发出, CONNACK 稍后由
		 * mqtt_input() 收到并触发 MQTT_EVT_CONNACK 事件 */
		LOG_INF("MQTT CONNECT sent, waiting for CONNACK...");
		int connack_wait = 50;	/* 50 x 100ms = 5 秒超时 */
		while (!mqtt_connected && connack_wait-- > 0) {
			rc = mqtt_input(&client_ctx);
			if (rc != 0 && rc != -EAGAIN) {
				break;
			}
			k_msleep(100);
		}
		if (!mqtt_connected) {
			LOG_WRN("CONNACK timeout, reconnecting");
			mqtt_disconnect(&client_ctx);
			k_msleep(MQTT_RECONNECT_DELAY_MS);
			continue;
		}

		/* 连接成功, 进入发布循环 */
		LOG_INF("MQTT publish loop started: topic=%s, period=%d ms",
			MQTT_TOPIC, MQTT_PUBLISH_PERIOD_MS);

		while (mqtt_connected) {
			char payload[8];
			int len = snprintf(payload, sizeof(payload),
					   "%d", percent_value);

			struct mqtt_publish_param param = {
				.message.topic.qos = MQTT_QOS_0_AT_MOST_ONCE,
				.message.topic.topic.utf8 = (uint8_t *)MQTT_TOPIC,
				.message.topic.topic.size = sizeof(MQTT_TOPIC) - 1,
				.message.payload.data = payload,
				.message.payload.len = len,
			};

			rc = mqtt_publish(&client_ctx, &param);
			if (rc != 0) {
				LOG_ERR("MQTT publish failed %d, reconnecting", rc);
				break;
			}

			/* 处理 broker 下行数据(心跳响应等) */
			rc = mqtt_input(&client_ctx);
			if (rc != 0 && rc != -EAGAIN) {
				LOG_ERR("mqtt_input failed %d, reconnecting", rc);
				break;
			}

			/* 保活(必要时发 ping) */
			rc = mqtt_live(&client_ctx);
			if (rc != 0 && rc != -EAGAIN) {
				LOG_ERR("mqtt_live failed %d, reconnecting", rc);
				break;
			}

			k_msleep(MQTT_PUBLISH_PERIOD_MS);
		}

		mqtt_disconnect(&client_ctx);
	}
}

/* ==== 公开接口 ==== */
void mqtt_set_percent(int8_t percent)
{
	percent_value = percent;
}

void mqtt_client_start(void)
{
	k_thread_create(&mqtt_thread_data, mqtt_stack,
			K_THREAD_STACK_SIZEOF(mqtt_stack),
			mqtt_thread_fn, NULL, NULL, NULL,
			K_LOWEST_APPLICATION_THREAD_PRIO, 0, K_NO_WAIT);
	k_thread_name_set(&mqtt_thread_data, "mqtt_pub");
}
```

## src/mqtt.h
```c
#ifndef __MQTT_H__
#define __MQTT_H__

#ifdef __cplusplus
extern "C" {
#endif

/** 启动 MQTT 客户端线程(自动重连,WiFi 就绪前会一直重试) */
void mqtt_client_start(void);

/** 更新要发布的百分比值(由主循环周期调用) */
void mqtt_set_percent(int8_t percent);

#ifdef __cplusplus
}
#endif

#endif /* __MQTT_H__ */
```

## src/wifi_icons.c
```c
/* 由脚本生成的 WiFi 信号条图标 (16x16, LV_IMG_CF_ALPHA_1BIT, MSB在前)
 * 左矮右高, 底部对齐; 1/2/3/4 格对应 wifi_1..wifi_4 */
#include <lvgl.h>
#include "lv_wifi.h"

static const uint8_t wifi_4_map[] = {
	0x00, 0x0e, 0x00, 0x0e, 0x00, 0x0e, 0x00, 0x0e,
	0x00, 0xee, 0x00, 0xee, 0x00, 0xee, 0x00, 0xee,
	0x0e, 0xee, 0x0e, 0xee, 0x0e, 0xee, 0x0e, 0xee,
	0xee, 0xee, 0xee, 0xee, 0xee, 0xee, 0xee, 0xee,
};

const lv_img_dsc_t wifi_4 = {
	.header = {.cf = LV_IMG_CF_ALPHA_1BIT, .always_zero = 0, .w = 16, .h = 16},
	.data_size = sizeof(wifi_4_map),
	.data = wifi_4_map,
};

static const uint8_t wifi_3_map[] = {
	0x00, 0x00, 0x00, 0x00, 0x00, 0x00, 0x00, 0x00,
	0x00, 0xe0, 0x00, 0xe0, 0x00, 0xe0, 0x00, 0xe0,
	0x0e, 0xe0, 0x0e, 0xe0, 0x0e, 0xe0, 0x0e, 0xe0,
	0xee, 0xe0, 0xee, 0xe0, 0xee, 0xe0, 0xee, 0xe0,
};

const lv_img_dsc_t wifi_3 = {
	.header = {.cf = LV_IMG_CF_ALPHA_1BIT, .always_zero = 0, .w = 16, .h = 16},
	.data_size = sizeof(wifi_3_map),
	.data = wifi_3_map,
};

static const uint8_t wifi_2_map[] = {
	0x00, 0x00, 0x00, 0x00, 0x00, 0x00, 0x00, 0x00,
	0x00, 0x00, 0x00, 0x00, 0x00, 0x00, 0x00, 0x00,
	0x0e, 0x00, 0x0e, 0x00, 0x0e, 0x00, 0x0e, 0x00,
	0xee, 0x00, 0xee, 0x00, 0xee, 0x00, 0xee, 0x00,
};

const lv_img_dsc_t wifi_2 = {
	.header = {.cf = LV_IMG_CF_ALPHA_1BIT, .always_zero = 0, .w = 16, .h = 16},
	.data_size = sizeof(wifi_2_map),
	.data = wifi_2_map,
};

static const uint8_t wifi_1_map[] = {
	0x00, 0x00, 0x00, 0x00, 0x00, 0x00, 0x00, 0x00,
	0x00, 0x00, 0x00, 0x00, 0x00, 0x00, 0x00, 0x00,
	0x00, 0x00, 0x00, 0x00, 0x00, 0x00, 0x00, 0x00,
	0xe0, 0x00, 0xe0, 0x00, 0xe0, 0x00, 0xe0, 0x00,
};

const lv_img_dsc_t wifi_1 = {
	.header = {.cf = LV_IMG_CF_ALPHA_1BIT, .always_zero = 0, .w = 16, .h = 16},
	.data_size = sizeof(wifi_1_map),
	.data = wifi_1_map,
};
```
